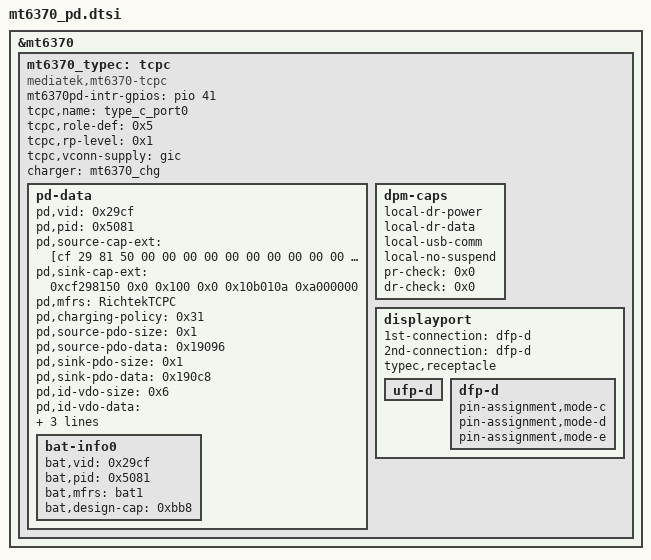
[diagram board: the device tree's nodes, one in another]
// SPDX-License-Identifier: GPL-2.0-only
/* MediaTek MT6370 USB Type-C / PD Controller bindings for Kernel 6.6 */

&mt6370 {
    mt6370_typec: tcpc {
        compatible = "mediatek,mt6370-tcpc";
        mt6370pd-intr-gpios = <&pio 41 GPIO_ACTIVE_HIGH>;
        tcpc,name = "type_c_port0";
        tcpc,role-def = <0x5>;
        tcpc,rp-level = <0x1>;
        tcpc,vconn-supply = <&gic>;
        charger = <&mt6370_chg>;
        pd-data {
            pd,vid = <0x29cf>;
            pd,pid = <0x5081>;
            pd,source-cap-ext = [cf 29 81 50 00 00 00 00 00 00 00 00 00 00 00 00 00 00 00 00 00 00 01 07 00];
            pd,sink-cap-ext = <0xcf298150 0x0 0x100 0x0 0x10b010a 0xa000000>;
            pd,mfrs = "RichtekTCPC";
            pd,charging-policy = <0x31>;
            pd,source-pdo-size = <0x1>;
            pd,source-pdo-data = <0x19096>;
            pd,sink-pdo-size = <0x1>;
            pd,sink-pdo-data = <0x190c8>;
            pd,id-vdo-size = <0x6>;
            pd,id-vdo-data = <0xd14029cf 0x0 0x50810000 0x61000000 0x0 0x41000000>;
            bat,nr = <0x1>;
            pd,country-nr = <0x0>;
            bat-info0 {
                bat,vid = <0x29cf>;
                bat,pid = <0x5081>;
                bat,mfrs = "bat1";
                bat,design-cap = <0xbb8>;
            };
        };
        dpm-caps {
            local-dr-power;
            local-dr-data;
            local-usb-comm;
            local-no-suspend;
            pr-check = <0x0>;
            dr-check = <0x0>;
        };
        displayport {
            1st-connection = "dfp-d";
            2nd-connection = "dfp-d";
            typec,receptacle;
            ufp-d {
            };
            dfp-d {
                pin-assignment,mode-c;
                pin-assignment,mode-d;
                pin-assignment,mode-e;
            };
        };
    };
};
